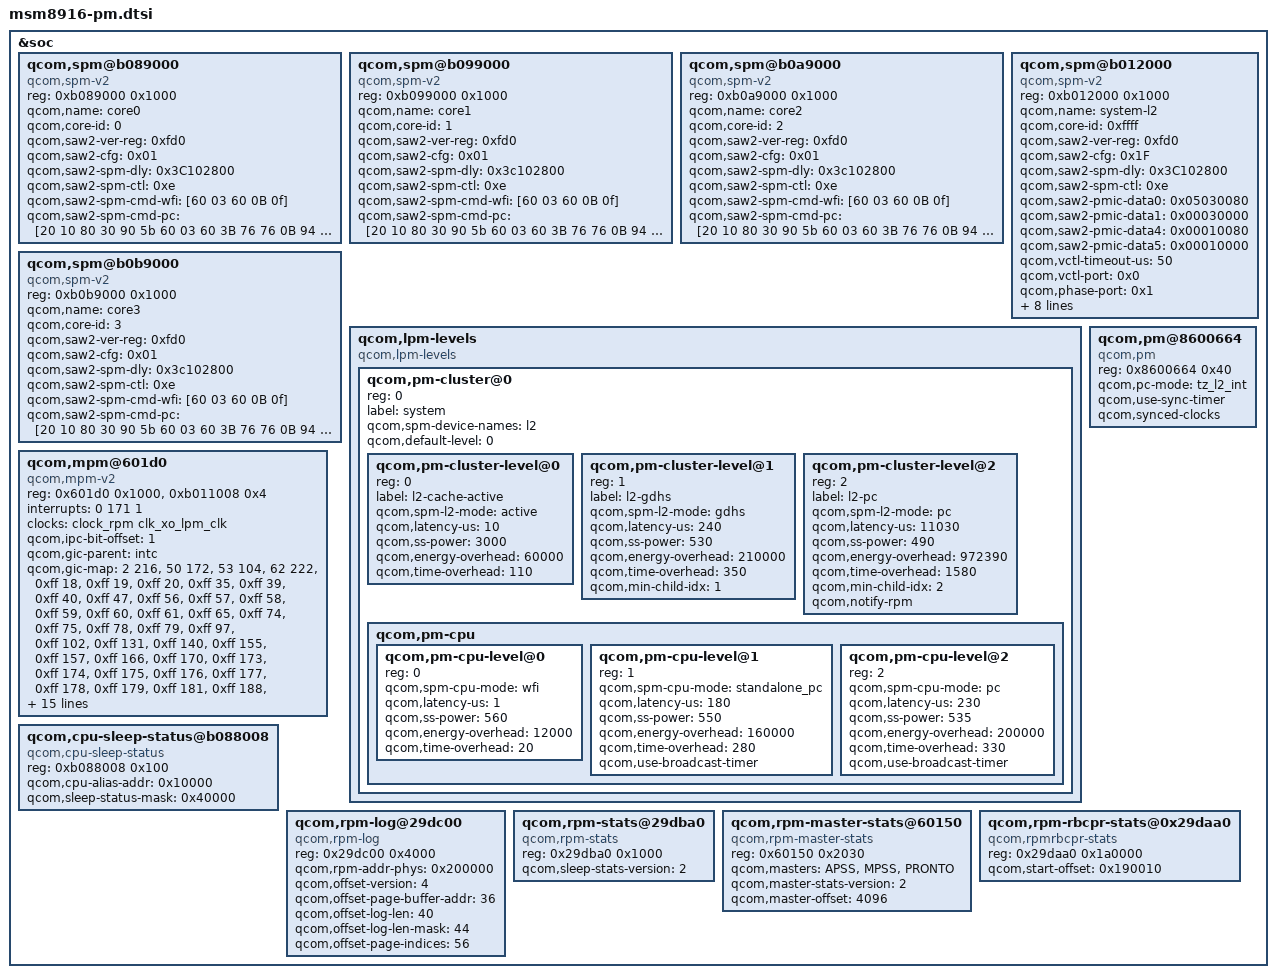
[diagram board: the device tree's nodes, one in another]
/* Copyright (c) 2013-2014, The Linux Foundation. All rights reserved.
 *
 * This program is free software; you can redistribute it and/or modify
 * it under the terms of the GNU General Public License version 2 and
 * only version 2 as published by the Free Software Foundation.
 *
 * This program is distributed in the hope that it will be useful,
 * but WITHOUT ANY WARRANTY; without even the implied warranty of
 * MERCHANTABILITY or FITNESS FOR A PARTICULAR PURPOSE.  See the
 * GNU General Public License for more details.
 */

&soc {
	qcom,spm@b089000 {
		compatible = "qcom,spm-v2";
		#address-cells = <1>;
		#size-cells = <1>;
		reg = <0xb089000 0x1000>;
		qcom,name = "core0";
		qcom,core-id = <0>;
		qcom,saw2-ver-reg = <0xfd0>;
		qcom,saw2-cfg = <0x01>;
		qcom,saw2-spm-dly= <0x3C102800>;
		qcom,saw2-spm-ctl = <0xe>;
		qcom,saw2-spm-cmd-wfi = [60 03 60 0B 0f];
		qcom,saw2-spm-cmd-pc = [20 10 80 30 90 5b 60 03 60 3B 76 76 0B
		                94 5B 80 10 26 30 0f];
	};

	qcom,spm@b099000 {
		compatible = "qcom,spm-v2";
		#address-cells = <1>;
		#size-cells = <1>;
		reg = <0xb099000 0x1000>;
		qcom,name = "core1";
		qcom,core-id = <1>;
		qcom,saw2-ver-reg = <0xfd0>;
		qcom,saw2-cfg = <0x01>;
		qcom,saw2-spm-dly= <0x3c102800>;
		qcom,saw2-spm-ctl = <0xe>;
		qcom,saw2-spm-cmd-wfi = [60 03 60 0B 0f];
		qcom,saw2-spm-cmd-pc = [20 10 80 30 90 5b 60 03 60 3B 76 76 0B
		                94 5B 80 10 26 30 0f];
	};

	qcom,spm@b0a9000 {
		compatible = "qcom,spm-v2";
		#address-cells = <1>;
		#size-cells = <1>;
		reg = <0xb0a9000 0x1000>;
		qcom,name = "core2";
		qcom,core-id = <2>;
		qcom,saw2-ver-reg = <0xfd0>;
		qcom,saw2-cfg = <0x01>;
		qcom,saw2-spm-dly= <0x3c102800>;
		qcom,saw2-spm-ctl = <0xe>;
		qcom,saw2-spm-cmd-wfi = [60 03 60 0B 0f];
		qcom,saw2-spm-cmd-pc = [20 10 80 30 90 5b 60 03 60 3B 76 76 0B
		                94 5B 80 10 26 30 0f];
	};

	qcom,spm@b0b9000 {
		compatible = "qcom,spm-v2";
		#address-cells = <1>;
		#size-cells = <1>;
		reg = <0xb0b9000 0x1000>;
		qcom,name = "core3";
		qcom,core-id = <3>;
		qcom,saw2-ver-reg = <0xfd0>;
		qcom,saw2-cfg = <0x01>;
		qcom,saw2-spm-dly= <0x3c102800>;
		qcom,saw2-spm-ctl = <0xe>;
		qcom,saw2-spm-cmd-wfi = [60 03 60 0B 0f];
		qcom,saw2-spm-cmd-pc = [20 10 80 30 90 5b 60 03 60 3B 76 76 0B
		                94 5B 80 10 26 30 0f];
	};

	qcom,spm@b012000 {
		compatible = "qcom,spm-v2";
		#address-cells = <1>;
		#size-cells = <1>;
		reg = <0xb012000 0x1000>;
		qcom,name = "system-l2";
		qcom,core-id = <0xffff>; /* L2/APCS SAW */
		qcom,saw2-ver-reg = <0xfd0>;
		qcom,saw2-cfg = <0x1F>;
		qcom,saw2-spm-dly= <0x3C102800>;
		qcom,saw2-spm-ctl = <0xe>;
		qcom,saw2-pmic-data0 = <0x05030080>;
		qcom,saw2-pmic-data1 = <0x00030000>;
		qcom,saw2-pmic-data4 = <0x00010080>;
		qcom,saw2-pmic-data5 = <0x00010000>;
		qcom,vctl-timeout-us = <50>;
		qcom,vctl-port = <0x0>;
		qcom,phase-port = <0x1>;
		qcom,pfm-port = <0x2>;
		qcom,cpu-vctl-mask = <0xf>;
		qcom,supports-rpm-hs;
		qcom,saw2-spm-cmd-ret = [00 03 00 0f];
		qcom,saw2-spm-cmd-gdhs = [00 20 32 6B C0 E0 D0 42 F0 03 50 4E
				02 02 D0 E0 C0 22 6B 02 32 52 F0 0F];
		qcom,saw2-spm-cmd-pc = [00 32 B0 10 E0 D0 6B C0 42 51 11 03 01 41
				B0 50 4E 02 02 C0 D0 12 E0 6B 02 32 50 0F];
	};


	qcom,lpm-levels {
		compatible = "qcom,lpm-levels";
		#address-cells = <1>;
		#size-cells = <0>;

		qcom,pm-cluster@0{
			reg = <0>;
			#address-cells = <1>;
			#size-cells = <0>;
			label = "system";
			qcom,spm-device-names = "l2";
			qcom,default-level = <0>;

			qcom,pm-cluster-level@0{
				reg = <0>;
				label = "l2-cache-active";
				qcom,spm-l2-mode = "active";
				qcom,latency-us = <10>;
				qcom,ss-power = <3000>;
				qcom,energy-overhead = <60000>;
				qcom,time-overhead = <110>;
			};

			qcom,pm-cluster-level@1{
				reg = <1>;
				label = "l2-gdhs";
				qcom,spm-l2-mode = "gdhs";
				qcom,latency-us = <240>;
				qcom,ss-power = <530>;
				qcom,energy-overhead = <210000>;
				qcom,time-overhead = <350>;
				qcom,min-child-idx = <1>;
			};

			qcom,pm-cluster-level@2{
				reg = <2>;
				label = "l2-pc";
				qcom,spm-l2-mode = "pc";
				qcom,latency-us = <11030>;
				qcom,ss-power = <490>;
				qcom,energy-overhead = <972390>;
				qcom,time-overhead = <1580>;
				qcom,min-child-idx = <2>;
				qcom,notify-rpm;
			};

			qcom,pm-cpu {
				#address-cells = <1>;
				#size-cells = <0>;
				qcom,pm-cpu-level@0 {
					reg = <0>;
					qcom,spm-cpu-mode = "wfi";
					qcom,latency-us = <1>;
					qcom,ss-power = <560>;
					qcom,energy-overhead = <12000>;
					qcom,time-overhead = <20>;
				};

				qcom,pm-cpu-level@1 {
					reg = <1>;
					qcom,spm-cpu-mode = "standalone_pc";
					qcom,latency-us = <180>;
					qcom,ss-power = <550>;
					qcom,energy-overhead = <160000>;
					qcom,time-overhead = <280>;
					qcom,use-broadcast-timer;
				};

				qcom,pm-cpu-level@2 {
					reg = <2>;
					qcom,spm-cpu-mode = "pc";
					qcom,latency-us = <230>;
					qcom,ss-power = <535>;
					qcom,energy-overhead = <200000>;
					qcom,time-overhead = <330>;
					qcom,use-broadcast-timer;
				};
			};
		};
	};

	qcom,mpm@601d0 {
		compatible = "qcom,mpm-v2";
		reg = <0x601d0 0x1000>, /* MSM_RPM_MPM_BASE 4K */
		    <0xb011008 0x4>;
		reg-names = "vmpm", "ipc";
		interrupts = <0 171 1>;
		clocks = <&clock_rpm clk_xo_lpm_clk>;
		clock-names = "xo";

		qcom,ipc-bit-offset = <1>;

		qcom,gic-parent = <&intc>;
		qcom,gic-map = <2 216>, /* tsens_upper_lower_int */
			<50 172>, /* usb1_hs_async_wakeup_irq */
			<53 104>, /* mdss_irq */
			<62 222>, /* ee0_krait_hlos_spmi_periph_irq */
			<0xff 18>,  /* APC_qgicQTmrSecPhysIrptReq */
			<0xff 19>,  /* APC_qgicQTmrNonSecPhysIrptReq */
			<0xff 20>,  /* qgicQTmrVirtIrptReq */
			<0xff 35>,  /* WDT_barkInt */
			<0xff 39>,  /* arch_mem_timer */
			<0xff 40>,  /* qtmr_phy_irq[0] */
			<0xff 47>,  /* rbif_irq[0] */
			<0xff 56>,  /* q6_wdog_expired_irq */
			<0xff 57>,  /* mss_to_apps_irq(0) */
			<0xff 58>,  /* mss_to_apps_irq(1) */
			<0xff 59>,  /* mss_to_apps_irq(2) */
			<0xff 60>,  /* mss_to_apps_irq(3) */
			<0xff 61>,  /* mss_a2_bam_irq */
			<0xff 65>,  /* o_gc_sys_irq[0] */
			<0xff 74>,  /* smmu_bus_intr[2] */
			<0xff 75>,  /* smmu_bus_intr[3] */
			<0xff 78>,  /* smmu_bus_intr[5] */
			<0xff 79>,  /* smmu_bus_intr[6] */
			<0xff 97>,  /* smmu_bus_intr[10] */
			<0xff 102>, /* smmu_bus_intr[14] */
			<0xff 131>, /* qup_irq */
			<0xff 140>, /* uart_dm_intr */
			<0xff 155>, /* sdc1_irq(0) */
			<0xff 157>, /* sdc2_irq(0) */
			<0xff 166>, /* usb_hs_irq */
			<0xff 170>, /* sdc1_pwr_cmd_irq */
			<0xff 173>, /* o_wcss_apss_smd_hi */
			<0xff 174>, /* o_wcss_apss_smd_med */
			<0xff 175>, /* o_wcss_apss_smd_low */
			<0xff 176>, /* o_wcss_apss_smsm_irq */
			<0xff 177>, /* o_wcss_apss_wlan_data_xfer_done */
			<0xff 178>, /* o_wcss_apss_wlan_rx_data_avail */
			<0xff 179>, /* o_wcss_apss_asic_intr */
			<0xff 181>, /* o_wcss_apss_wdog_bite_and_reset_rdy */

			<0xff 188>, /* lpass_irq_out_apcs(0) */
			<0xff 189>, /* lpass_irq_out_apcs(1) */
			<0xff 190>, /* lpass_irq_out_apcs(2) */
			<0xff 191>, /* lpass_irq_out_apcs(3) */
			<0xff 192>, /* lpass_irq_out_apcs(4) */
			<0xff 193>, /* lpass_irq_out_apcs(5) */
			<0xff 194>, /* lpass_irq_out_apcs(6) */
			<0xff 195>, /* lpass_irq_out_apcs(7) */
			<0xff 196>, /* lpass_irq_out_apcs(8) */
			<0xff 197>, /* lpass_irq_out_apcs(9) */
			<0xff 198>, /* coresight-tmc-etr interrupt */
			<0xff 200>, /* rpm_ipc(4) */
			<0xff 201>, /* rpm_ipc(5) */
			<0xff 202>, /* rpm_ipc(6) */
			<0xff 203>, /* rpm_ipc(7) */
			<0xff 204>, /* rpm_ipc(24) */
			<0xff 205>, /* rpm_ipc(25) */
			<0xff 206>, /* rpm_ipc(26) */
			<0xff 207>, /* rpm_ipc(27) */
			<0xff 239>, /* crypto_bam_irq[1]*/
			<0xff 240>, /* summary_irq_kpss */
			<0xff 253>, /* sdc2_pwr_cmd_irq */
			<0xff 269>, /* rpm_wdog_expired_irq */
			<0xff 270>, /* blsp1_bam_irq[0] */
			<0xff 275>, /* rpm_ipc(30) */
			<0xff 276>; /* rpm_ipc(31) */

		qcom,gpio-parent = <&msm_gpio>;
		qcom,gpio-map = <3  108 >,
			<4  1 >,
			<5  5 >,
			<6  9 >,
			<7  107>,
			<8  98>,
			<9  97>,
			<10  11>,
			<11  69>,
			<12  12>,
			<13  13>,
			<14  20>,
			<15  62>,
			<16  54>,
			<17  21>,
			<18  52>,
			<19  25>,
			<20  51>,
			<21  50>,
			<22  28>,
			<23  31>,
			<24  34>,
			<25  35>,
			<26  36>,
			<27  37>,
			<28  38>,
			<29  49>,
			<30  109>,
			<31  110>,
			<32  111>,
			<33  112>,
			<34  113>,
			<35  114>,
			<36  115>,
			<37  117>,
			<38  118>,
			<39  120>,
			<40  121>,
			<50  66>,
			<51  68>;
	};

	qcom,pm@8600664 {
		compatible = "qcom,pm";
		reg = <0x8600664 0x40>;
		qcom,pc-mode = "tz_l2_int";
		qcom,use-sync-timer;
		qcom,synced-clocks;
	};

	qcom,cpu-sleep-status@b088008{
		compatible = "qcom,cpu-sleep-status";
		reg = <0xb088008 0x100>;
		qcom,cpu-alias-addr = <0x10000>;
		qcom,sleep-status-mask= <0x40000>;
	};

	qcom,rpm-log@29dc00 {
		compatible = "qcom,rpm-log";
		reg = <0x29dc00 0x4000>;
		qcom,rpm-addr-phys = <0x200000>;
		qcom,offset-version = <4>;
		qcom,offset-page-buffer-addr = <36>;
		qcom,offset-log-len = <40>;
		qcom,offset-log-len-mask = <44>;
		qcom,offset-page-indices = <56>;
	};

	qcom,rpm-stats@29dba0 {
		compatible = "qcom,rpm-stats";
		reg = <0x29dba0 0x1000>;
		reg-names = "phys_addr_base";
		qcom,sleep-stats-version = <2>;
	};

	qcom,rpm-master-stats@60150 {
		compatible = "qcom,rpm-master-stats";
		reg = <0x60150 0x2030>;
		qcom,masters = "APSS", "MPSS", "PRONTO";
		qcom,master-stats-version = <2>;
		qcom,master-offset = <4096>;
	};
	qcom,rpm-rbcpr-stats@0x29daa0  {
		compatible = "qcom,rpmrbcpr-stats";
		reg = <0x29daa0 0x1a0000>;
		qcom,start-offset = <0x190010>;
	};
};
